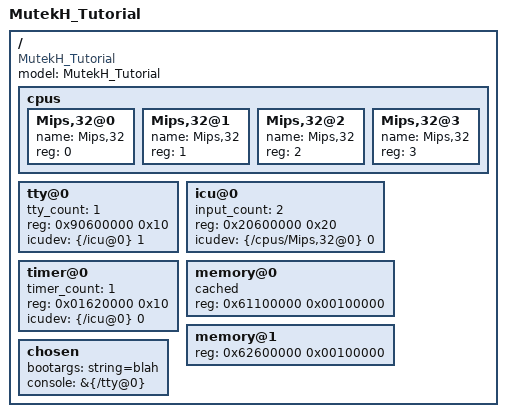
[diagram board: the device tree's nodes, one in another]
/dts-v1/;

/ {
	model = "MutekH_Tutorial";
	compatible = "MutekH_Tutorial";
	#address-cells = <1>;
	#size-cells = <1>;

	cpus {
		#address-cells = <1>;
		#size-cells = <0>;
		Mips,32@0 {
			name = "Mips,32";
			device_type = "cpu";
			reg = <0>;
		};

		Mips,32@1 {
			name = "Mips,32";
			device_type = "cpu";
			reg = <1>;
		};

		Mips,32@2 {
			name = "Mips,32";
			device_type = "cpu";
			reg = <2>;
		};

		Mips,32@3 {
			name = "Mips,32";
			device_type = "cpu";
			reg = <3>;
		};

	};

	tty@0 {
	    device_type = "soclib:tty";
		tty_count = <1>;
		reg = <0x90600000 0x10>;
		icudev = <&{/icu@0} 1>;
	};

	icu@0 {
	    device_type = "soclib:icu";
		input_count = <2>;
		reg = <0x20600000 0x20>;
		icudev = <&{/cpus/Mips,32@0} 0>;
	};

	timer@0 {
	    device_type = "soclib:timer";
		timer_count = <1>;
		reg = <0x01620000 0x10>;
		icudev = <&{/icu@0} 0>;
	};

	memory@0 {
		device_type = "memory";
		cached;
		memreg: reg = <0x61100000 0x00100000>;
	};

	memory@1 {
		device_type = "memory";
		memreg: reg = <0x62600000 0x00100000>;
	};

	chosen {
		bootargs = "string=blah";
		console = &{/tty@0};
	};

};
